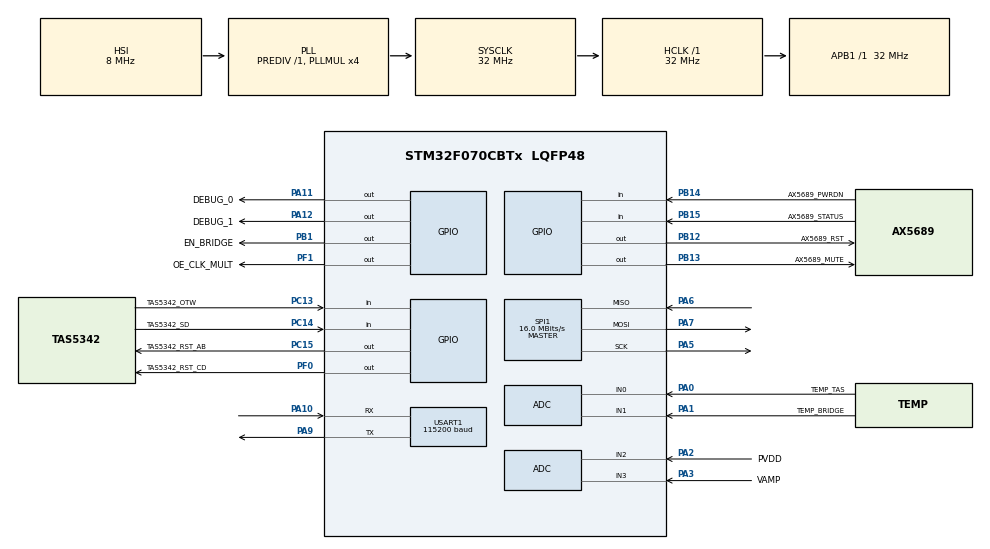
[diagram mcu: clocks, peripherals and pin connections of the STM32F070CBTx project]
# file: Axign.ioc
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ADC.ContinuousConvMode=ENABLE
ADC.SamplingTime=ADC_SAMPLETIME_239CYCLES_5
Mcu.Family=STM32F0
Mcu.Name=STM32F070CBTx
Mcu.Package=LQFP48
NVIC.TIM6_IRQn=true\:0\:0\:false\:false\:true\:true\:true
PA0.GPIO_Label=TEMP_TAS
PA0.Mode=IN0
PA0.Signal=ADC_IN0
PA1.GPIO_Label=TEMP_BRIDGE
PA1.Mode=IN1
PA1.Signal=ADC_IN1
PA10.Mode=Asynchronous
PA10.Signal=USART1_RX
PA11.GPIO_Label=DEBUG_0
PA11.Signal=GPIO_Output
PA12.GPIO_Label=DEBUG_1
PA12.Signal=GPIO_Output
PA13.Signal=IR_OUT
PA14.Signal=SYS_SWCLK
PA2.GPIO_Label=PVDD
PA2.Mode=IN2
PA2.Signal=ADC_IN2
PA3.GPIO_Label=VAMP
PA3.Mode=IN3
PA3.Signal=ADC_IN3
PA4.Signal=SPI1_NSS
PA5.Mode=Full_Duplex_Master
PA5.Signal=SPI1_SCK
PA6.Mode=Full_Duplex_Master
PA6.Signal=SPI1_MISO
PA7.Mode=Full_Duplex_Master
PA7.Signal=SPI1_MOSI
PA9.Mode=Asynchronous
PA9.Signal=USART1_TX
PB1.GPIO_Label=EN_BRIDGE
PB1.Signal=GPIO_Output
PB12.GPIO_Label=AX5689_RST
PB12.PinState=GPIO_PIN_SET
PB12.Signal=GPIO_Output
PB13.GPIO_Label=AX5689_MUTE
PB13.PinState=GPIO_PIN_RESET
PB13.Signal=GPIO_Output
PB14.GPIO_Label=AX5689_PWRDN
PB14.Signal=GPIO_Input
PB15.GPIO_Label=AX5689_STATUS
PB15.Signal=GPIO_Input
PC13.GPIO_Label=TAS5342_OTW
PC13.GPIO_PuPd=GPIO_PULLUP
PC13.Signal=GPIO_Input
PC14-OSC32_IN.GPIO_Label=TAS5342_SD
PC14-OSC32_IN.GPIO_PuPd=GPIO_PULLUP
PC14-OSC32_IN.Signal=GPIO_Input
PC15-OSC32_OUT.GPIO_Label=TAS5342_RST_AB
PC15-OSC32_OUT.Signal=GPIO_Output
PF0-OSC_IN.GPIO_Label=TAS5342_RST_CD
PF0-OSC_IN.Signal=GPIO_Output
PF1-OSC_OUT.GPIO_Label=OE_CLK_MULT
PF1-OSC_OUT.Signal=GPIO_Output
ProjectManager.HeapSize=0x200
ProjectManager.StackSize=0x400
ProjectManager.TargetToolchain=STM32CubeIDE
RCC.AHBFreq_Value=32000000
RCC.APB1Freq_Value=32000000
RCC.APB1TimFreq_Value=32000000
RCC.HCLKFreq_Value=32000000
RCC.PLLMUL=RCC_PLL_MUL4
RCC.SYSCLKFreq_VALUE=32000000
RCC.SYSCLKSource=RCC_SYSCLKSOURCE_PLLCLK
SPI1.CalculateBaudRate=16.0 MBits/s
SPI1.DataSize=SPI_DATASIZE_8BIT
SPI1.Direction=SPI_DIRECTION_2LINES
SPI1.Mode=SPI_MODE_MASTER
SPI1.VirtualType=VM_MASTER
TIM6.AutoReloadPreload=TIM_AUTORELOAD_PRELOAD_ENABLE
TIM6.Period=3200
TIM6.Prescaler=1000
USART1.BaudRate=115200
USART1.VirtualMode-Asynchronous=VM_ASYNC
VP_TIM6_VS_ClockSourceINT.Mode=Enable_Timer
board=custom

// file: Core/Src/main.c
/* USER CODE BEGIN Header */
/**
  ******************************************************************************
  * @file           : main.c
  * @brief          : Main program body
  ******************************************************************************
  * @attention
  *
  * <h2><center>&copy; Copyright (c) 2021 STMicroelectronics.
  * All rights reserved.</center></h2>
  *
  * This software component is licensed by ST under BSD 3-Clause license,
  * the "License"; You may not use this file except in compliance with the
  * License. You may obtain a copy of the License at:
  *                        opensource.org/licenses/BSD-3-Clause
  *
  ******************************************************************************
  */
/* USER CODE END Header */
#include "main.h"
#include "adc.h"
#include "spi.h"
#include "tim.h"
#include "usart.h"
#include "gpio.h"

void SystemClock_Config(void);

int main(void)
{

  /* MCU Configuration--------------------------------------------------------*/

  /* Reset of all peripherals, Initializes the Flash interface and the Systick. */
  HAL_Init();

  /* Configure the system clock */
  SystemClock_Config();

  /* Initialize all configured peripherals */
  MX_GPIO_Init();
  MX_ADC_Init();
  MX_SPI1_Init();
  MX_USART1_UART_Init();
  MX_TIM6_Init();
  /* USER CODE BEGIN 2 */
  console_printf("Hello Axign ! \r\n");
  HAL_Delay(100);
  //enable TAS5342
  HAL_GPIO_WritePin(TAS5342_RST_AB_GPIO_Port, TAS5342_RST_AB_Pin, GPIO_PIN_SET);
  HAL_GPIO_WritePin(TAS5342_RST_CD_GPIO_Port, TAS5342_RST_CD_Pin, GPIO_PIN_SET);

  //enable Bridge
  HAL_GPIO_WritePin(EN_BRIDGE_GPIO_Port, EN_BRIDGE_Pin, GPIO_PIN_SET);
  TIM6_IRQ_start();
  /* USER CODE END 2 */

  /* Infinite loop */
  while (1)
  {

  }
}

void SystemClock_Config(void)
{
  RCC_OscInitTypeDef RCC_OscInitStruct = {0};
  RCC_ClkInitTypeDef RCC_ClkInitStruct = {0};
  RCC_PeriphCLKInitTypeDef PeriphClkInit = {0};

  /** Initializes the RCC Oscillators according to the specified parameters
  * in the RCC_OscInitTypeDef structure.
  */
  RCC_OscInitStruct.OscillatorType = RCC_OSCILLATORTYPE_HSI|RCC_OSCILLATORTYPE_HSI14;
  RCC_OscInitStruct.HSIState = RCC_HSI_ON;
  RCC_OscInitStruct.HSI14State = RCC_HSI14_ON;
  RCC_OscInitStruct.HSICalibrationValue = RCC_HSICALIBRATION_DEFAULT;
  RCC_OscInitStruct.HSI14CalibrationValue = 16;
  RCC_OscInitStruct.PLL.PLLState = RCC_PLL_ON;
  RCC_OscInitStruct.PLL.PLLSource = RCC_PLLSOURCE_HSI;
  RCC_OscInitStruct.PLL.PLLMUL = RCC_PLL_MUL4;
  RCC_OscInitStruct.PLL.PREDIV = RCC_PREDIV_DIV1;
  if (HAL_RCC_OscConfig(&RCC_OscInitStruct) != HAL_OK)
  {
    Error_Handler();
  }
  /** Initializes the CPU, AHB and APB buses clocks
  */
  RCC_ClkInitStruct.ClockType = RCC_CLOCKTYPE_HCLK|RCC_CLOCKTYPE_SYSCLK
                              |RCC_CLOCKTYPE_PCLK1;
  RCC_ClkInitStruct.SYSCLKSource = RCC_SYSCLKSOURCE_PLLCLK;
  RCC_ClkInitStruct.AHBCLKDivider = RCC_SYSCLK_DIV1;
  RCC_ClkInitStruct.APB1CLKDivider = RCC_HCLK_DIV1;

  if (HAL_RCC_ClockConfig(&RCC_ClkInitStruct, FLASH_LATENCY_1) != HAL_OK)
  {
    Error_Handler();
  }
  PeriphClkInit.PeriphClockSelection = RCC_PERIPHCLK_USART1;
  PeriphClkInit.Usart1ClockSelection = RCC_USART1CLKSOURCE_PCLK1;
  if (HAL_RCCEx_PeriphCLKConfig(&PeriphClkInit) != HAL_OK)
  {
    Error_Handler();
  }
}

void Error_Handler(void)
{
  /* USER CODE BEGIN Error_Handler_Debug */
	color_console(RED_CONSOLE);
	console_printf("ERROR HANDLER\r\n");
	color_console(INIT_COLOR_CONSOLE);
  /* User can add his own implementation to report the HAL error return state */

  /* USER CODE END Error_Handler_Debug */
}

/************************ (C) COPYRIGHT STMicroelectronics *****END OF FILE****/
